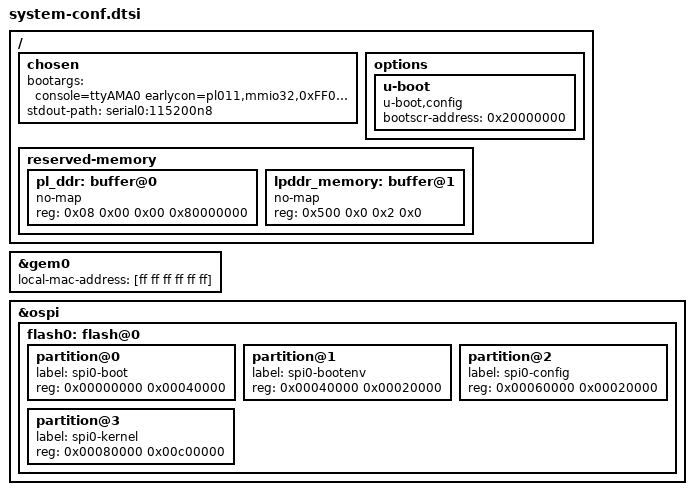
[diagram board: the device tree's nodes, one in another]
/*
 * CAUTION: This file is automatically generated by PetaLinux SDK.
 * DO NOT modify this file
 */


/ {
	chosen {
		bootargs = "console=ttyAMA0 earlycon=pl011,mmio32,0xFF000000,115200n8 root=/dev/ram0 rw init_fatal_sh=1 cma=1000M";
		stdout-path = "serial0:115200n8";
	};

	options {
		u-boot {
			compatible = "u-boot,config";
			bootscr-address = /bits/ 64 <0x20000000>;
		};
	};

    reserved-memory {
            #address-cells = <2>;
            #size-cells = <2>;
            ranges;
            pl_ddr: buffer@0
            {
            no-map;
            reg = <0x08 0x00 0x00 0x80000000>;
            };

            lpddr_memory: buffer@1
            {
            no-map;
            reg = <0x500 0x0 0x2 0x0>;
            };

    };
};

&gem0 {
	local-mac-address = [ff ff ff ff ff ff];
};

&ospi {
	#address-cells = <1>;
	#size-cells = <0>;
	flash0: flash@0 {
		/delete-node/ partition@0;
		/delete-node/ partition@100000;
		/delete-node/ partition@600000;
		/delete-node/ partition@620000;
		/delete-node/ partition@c00000;
		partition@0 {
			label = "spi0-boot";
			reg = <0x00000000 0x00040000>;
		};
		partition@1 {
			label = "spi0-bootenv";
			reg = <0x00040000 0x00020000>;
		};
		partition@2 {
			label = "spi0-config";
			reg = <0x00060000 0x00020000>;
		};
		partition@3 {
			label = "spi0-kernel";
			reg = <0x00080000 0x00c00000>;
		};
	};
};

